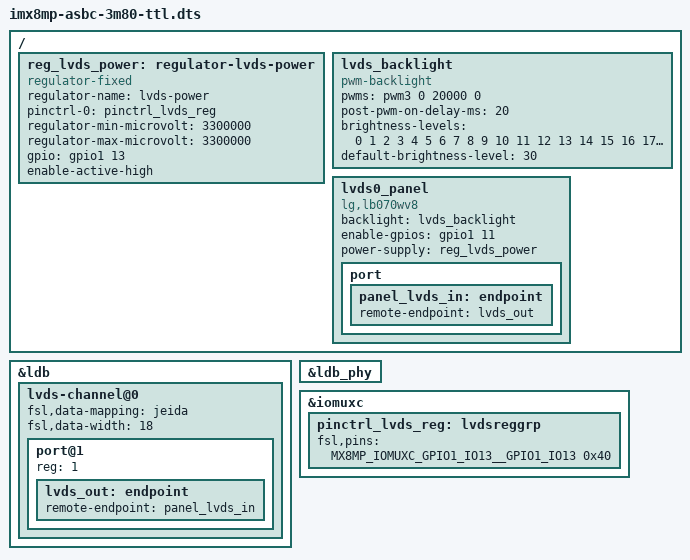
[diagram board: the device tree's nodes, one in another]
// SPDX-License-Identifier: GPL-2.0+

#include "imx8mp-asbc-3m80.dts"
	
/ {
	/* TTL */
	reg_lvds_power: regulator-lvds-power {
		compatible = "regulator-fixed";
		regulator-name = "lvds-power";
		pinctrl-names = "default";
		pinctrl-0 = <&pinctrl_lvds_reg>;
		regulator-min-microvolt = <3300000>;
		regulator-max-microvolt = <3300000>;
		gpio = <&gpio1 13 GPIO_ACTIVE_HIGH>;
		enable-active-high;
	};

	lvds_backlight: lvds_backlight {
		compatible = "pwm-backlight";
		pwms = <&pwm3 0 20000 0>;
		// pwms = <&pwm2 0 2000 0>;
		post-pwm-on-delay-ms = <20>;
		// pwm-off-delay-ms = <0>;
		status = "okay";

		brightness-levels = < 0  1  2  3  4  5  6  7  8  9
				     10 11 12 13 14 15 16 17 18 19
				     20 21 22 23 24 25 26 27 28 29
				     30 31 32 33 34 35 36 37 38 39
				     40 41 42 43 44 45 46 47 48 49
				     50 51 52 53 54 55 56 57 58 59
				     60 61 62 63 64 65 66 67 68 69
				     70 71 72 73 74 75 76 77 78 79
				     80 81 82 83 84 85 86 87 88 89
				     90 91 92 93 94 95 96 97 98 99
				    100>;
		default-brightness-level = <30>;
	};

	lvds0_panel {
		compatible = "lg,lb070wv8";
		backlight = <&lvds_backlight>;
		enable-gpios = <&gpio1 11 GPIO_ACTIVE_HIGH>;
		power-supply = <&reg_lvds_power>;

		port {
			panel_lvds_in: endpoint {
				remote-endpoint = <&lvds_out>;
			};
		};
	};

	// lvds0_panel {
	// 	compatible = "panel-lvds";
	// 	enable-gpios = <&gpio1 13 GPIO_ACTIVE_HIGH>;
	// 	width-mm = <155>;
	// 	height-mm = <94>;
	// 	label = "FG050722DSSWDG01";
	// 	data-mapping = "jeida-18";
	// 	// gpios = <&gpio1 13 GPIO_ACTIVE_HIGH>;
		
	// 	panel-timing {
	// 		clock-frequency = <30260000>;
	// 		hactive = <800>;
	// 		vactive = <480>;
	// 		hback-porch = <100>;
	// 		hfront-porch = <100>;
	// 		vback-porch = <45>;
	// 		vfront-porch = <45>;
	// 		hsync-len = <48>;
	// 		vsync-len = <3>;
	// 		hsync-active = <0>;
	// 		vsync-active = <0>;
	// 		de-active = <1>;
	// 	};

	// 	port {
	// 		panel_lvds_in: endpoint {
	// 			remote-endpoint = <&lvds_out>;
	// 		};
	// 	};
	// };
};

/* ttl */

&ldb {
	status = "okay";
	
	lvds-channel@0 {
		fsl,data-mapping = "jeida";
		fsl,data-width = <18>;
		status = "okay";

		/delete-node/ port@1;

		port@1 {
			reg = <1>;

			lvds_out: endpoint {
				remote-endpoint = <&panel_lvds_in>;
			};
		};
	};
};

&ldb_phy {
	status = "okay";
};

&iomuxc {
	pinctrl_lvds_reg: lvdsreggrp {
		fsl,pins = <
			MX8MP_IOMUXC_GPIO1_IO13__GPIO1_IO13		0x40
		>;
	};
};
